# HC32F558 register map
File version: 1.0
CPU: CM4 r0p1, little endian, MPU, FPU, 4 interrupt priority bits
Registers are 32-bit, read-write, reset 0x0 unless marked. A register's access mark holds for its fields unless they carry their own. Offsets are from the block's base; [hi:lo] are bit positions; {n}, {i} and the like mark numbered series.

## MCANRAM
Base 0x4002D800
0x00 CKCR
  [1:0] ECCMOD
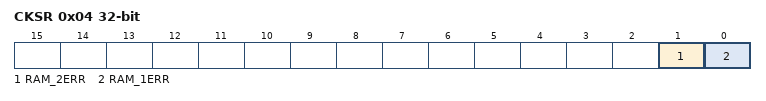
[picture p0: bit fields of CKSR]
0x04 CKSR
  [1] RAM_2ERR, [0] RAM_1ERR
0x08 EIEN
  [0] EIEN
0x0C EIBIT0
0x10 EIBIT1
  [6:0] EIBIT
0x14 ECCERRADDR ro
  [9:0] ECCERRADDR

## MPU
Base 0x40050000
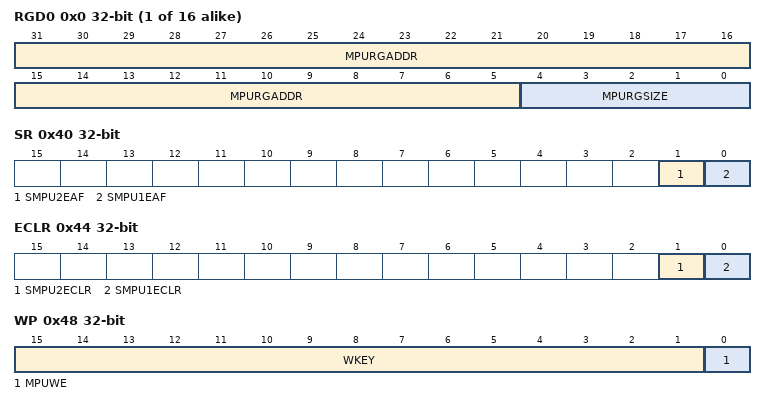
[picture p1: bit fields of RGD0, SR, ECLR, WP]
{0x0+4i} RGD{i} (i=0..15)
  [31:5] MPURGADDR, [4:0] MPURGSIZE
0x40 SR ro
  [1] SMPU2EAF, [0] SMPU1EAF
0x44 ECLR wo
  [1] SMPU2ECLR, [0] SMPU1ECLR
0x48 WP
  [15:1] WKEY wo, [0] MPUWE
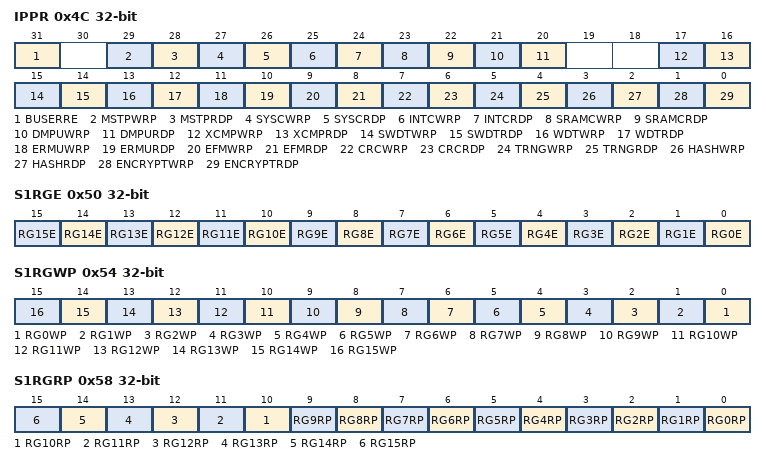
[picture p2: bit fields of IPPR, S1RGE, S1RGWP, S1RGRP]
0x4C IPPR
  [31] BUSERRE, [29] MSTPWRP, [28] MSTPRDP, [27] SYSCWRP, [26] SYSCRDP, [25] INTCWRP, [24] INTCRDP, [23] SRAMCWRP, [22] SRAMCRDP, [21] DMPUWRP, [20] DMPURDP, [17] XCMPWRP, [16] XCMPRDP, [15] SWDTWRP, [14] SWDTRDP, [13] WDTWRP, [12] WDTRDP, [11] ERMUWRP, [10] ERMURDP, [9] EFMWRP, [8] EFMRDP, [7] CRCWRP, [6] CRCRDP, [5] TRNGWRP, [4] TRNGRDP, [3] HASHWRP, [2] HASHRDP, [1] ENCRYPTWRP, [0] ENCRYPTRDP
0x50 S1RGE
  [n] RG{n}E (n=0..15)
0x54 S1RGWP
  [n] RG{n}WP (n=0..15)
0x58 S1RGRP
  [n] RG{n}RP (n=0..15)
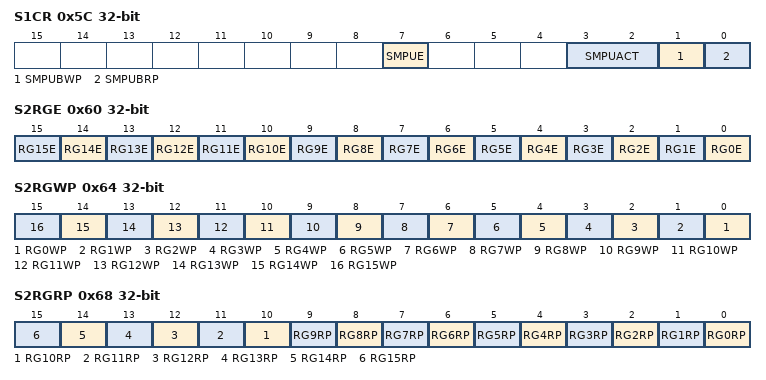
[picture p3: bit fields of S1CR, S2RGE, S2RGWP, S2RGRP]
0x5C S1CR
  [7] SMPUE, [3:2] SMPUACT, [1] SMPUBWP, [0] SMPUBRP
0x60 S2RGE
  [n] RG{n}E (n=0..15)
0x64 S2RGWP
  [n] RG{n}WP (n=0..15)
0x68 S2RGRP
  [n] RG{n}RP (n=0..15)
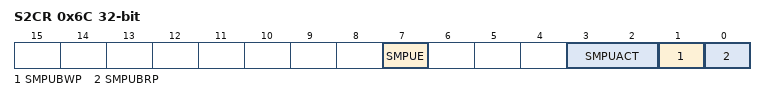
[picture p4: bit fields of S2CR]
0x6C S2CR
  [7] SMPUE, [3:2] SMPUACT, [1] SMPUBWP, [0] SMPUBRP

## OTS
Base 0x4004A800
0x00 CTL 16-bit
  [0] OTSE
0x08 PDR0 16-bit ro
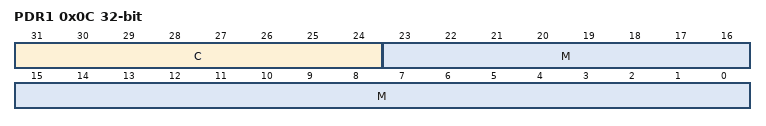
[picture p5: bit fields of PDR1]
0x0C PDR1 ro
  [31:24] C, [23:0] M

## PERIC
Base 0x40055400
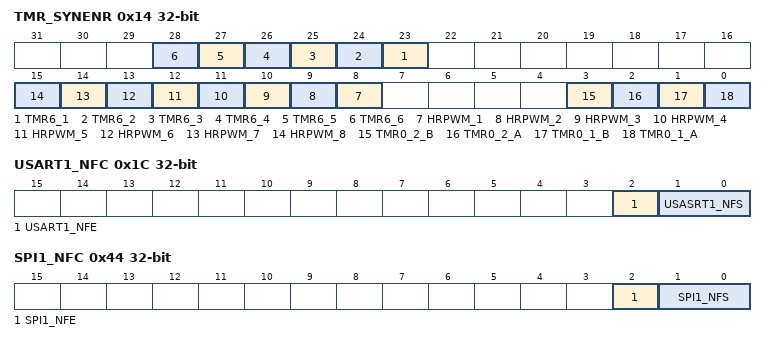
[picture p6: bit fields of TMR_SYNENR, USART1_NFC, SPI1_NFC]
0x14 TMR_SYNENR
  [n+22] TMR6_{n} (n=1..6), [n+7] HRPWM_{n} (n=1..8), [3] TMR0_2_B, [2] TMR0_2_A, [1] TMR0_1_B, [0] TMR0_1_A
0x1C USART1_NFC
  [2] USART1_NFE, [1:0] USASRT1_NFS
0x44 SPI1_NFC
  [2] SPI1_NFE, [1:0] SPI1_NFS

## PID1 — desc PID
Base 0x40057000
Same registers: PID2 0x40057100
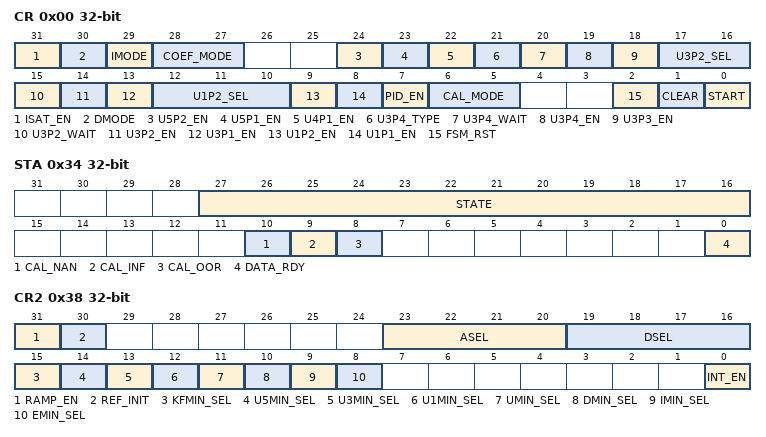
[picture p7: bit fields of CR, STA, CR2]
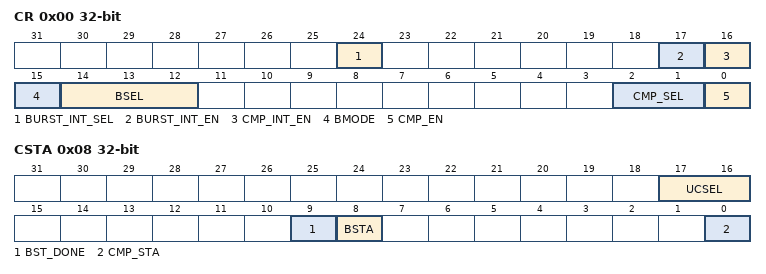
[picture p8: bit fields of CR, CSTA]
0x00 CR
  [31] ISAT_EN, [30] DMODE, [29] IMODE, [28:27] COEF_MODE, [24] U5P2_EN, [23] U5P1_EN, [22] U4P1_EN, [21] U3P4_TYPE, [20] U3P4_WAIT, [19] U3P4_EN, [18] U3P3_EN, [17:16] U3P2_SEL, [15] U3P2_WAIT, [14] U3P2_EN, [13] U3P1_EN, [12:10] U1P2_SEL, [9] U1P2_EN, [8] U1P1_EN, [7] PID_EN, [6:5] CAL_MODE, [2] FSM_RST wo, [1] CLEAR wo, [0] START wo
0x04 REF
0x08 AVAL
0x0C EMAX
0x10 EMIN
0x14 IMAX
0x18 IMIN
0x1C DMAX
0x20 DMIN
0x24 UMAX
0x28 UMIN
0x2C U1MAX
0x30 U1MIN
0x34 STA
  [27:16] STATE, [10] CAL_NAN, [9] CAL_INF, [8] CAL_OOR, [0] DATA_RDY
0x38 CR2
  [31] RAMP_EN, [30] REF_INIT, [23:20] ASEL, [19:16] DSEL, [15] KFMIN_SEL, [14] U5MIN_SEL, [13] U3MIN_SEL, [12] U1MIN_SEL, [11] UMIN_SEL, [10] DMIN_SEL, [9] IMIN_SEL, [8] EMIN_SEL, [0] INT_EN
{0x30+0xC*i} KP{i} (i=1..3)
{0x34+0xC*i} KI{i} (i=1..3)
{0x38+0xC*i} KD{i} (i=1..3)
0x60 KDF1
0x64 CSTH1
0x68 CSTH2
0x6C DLY1
0x70 DLY2
0x74 ERR ro
0x78 PVAL ro
0x7C IVAL ro
0x80 DVAL ro
0x84 U ro
{0x84+4i} U{i} ro (i=1..4)
0x98 U1P1
0x9C U3P1
0xA0 U4P1
0xA4 UF ro
0xA8 U1P2 ro
0xAC U3P2 ro
0xB0 U3P3
0xB4 U3P4 ro
0xB8 U5P1
0xBC U5P2
0xC0 U3MAX
0xC4 U3MIN
0xC8 U5MAX
0xCC U5MIN
0xD0 REF_FIN
0xD4 REF_STEP
0xD8 U5 ro
0xDC U5F ro
0xE0 KF_ACT ro
0xE4 KP_ACT ro
0xE8 KI_ACT ro
0xEC KD_ACT ro
0xF0 KDF2
0xF4 KDF3
0xF8 KDF_ACT ro

## PID_CMP
Base 0x40057400
0x00 CR
  [24] BURST_INT_SEL, [17] BURST_INT_EN, [16] CMP_INT_EN, [15] BMODE, [14:12] BSEL, [2:1] CMP_SEL, [0] CMP_EN
0x04 UC ro
0x08 CSTA
  [17:16] UCSEL ro, [9] BST_DONE, [8] BSTA, [0] CMP_STA
0x20 BTH
0x24 BMCMP ro
0x28 BMPU ro

## PLA
Base 0x4004FC00
0x00 GCTL
  [15:0] EN
0x0C STAT ro
  [15:0] OUT
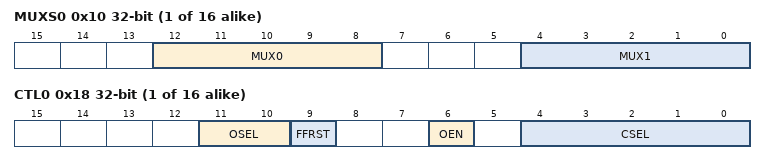
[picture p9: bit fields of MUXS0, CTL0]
{0x10+0xC*i} MUXS{i} (i=0..15)
  [12:8] MUX0, [4:0] MUX1
{0x14+0xC*i} LUTCTL{i} (i=0..15)
  [7:0] LUTCTL
{0x18+0xC*i} CTL{i} (i=0..15)
  [11:10] OSEL, [9] FFRST, [6] OEN, [4:0] CSEL

## PWC
Base 0x40048000; alternate view of CMU
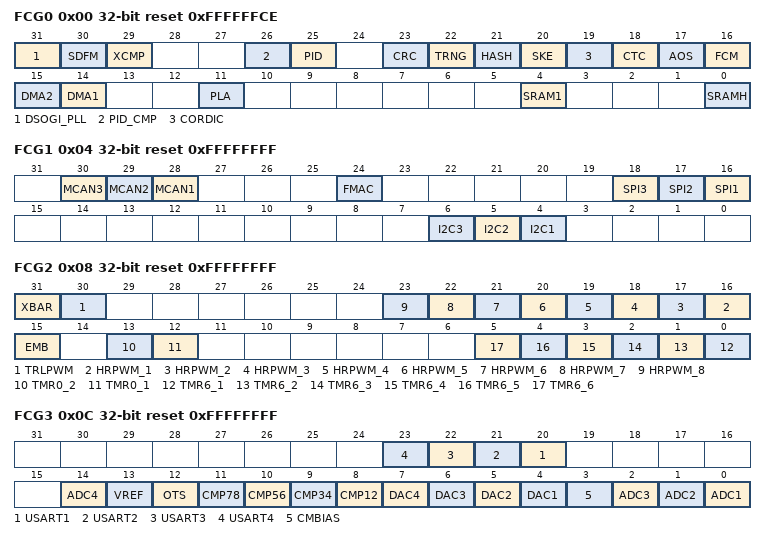
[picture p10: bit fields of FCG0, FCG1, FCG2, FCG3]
0x00 FCG0 reset 0xFFFFFFCE
  [31] DSOGI_PLL, [30] SDFM, [29] XCMP, [26] PID_CMP, [25] PID, [23] CRC, [22] TRNG, [21] HASH, [20] SKE, [19] CORDIC, [18] CTC, [17] AOS, [16] FCM, [15] DMA2, [14] DMA1, [11] PLA, [4] SRAM1, [0] SRAMH
0x04 FCG1 reset 0xFFFFFFFF
  [30] MCAN3, [29] MCAN2, [28] MCAN1, [24] FMAC, [18] SPI3, [17] SPI2, [16] SPI1, [6] I2C3, [5] I2C2, [4] I2C1
0x08 FCG2 reset 0xFFFFFFFF
  [31] XBAR, [30] TRLPWM, [n+15] HRPWM_{n} (n=1..8), [15] EMB, [13] TMR0_2, [12] TMR0_1, [n-1] TMR6_{n} (n=1..6)
0x0C FCG3 reset 0xFFFFFFFF
  [n+19] USART{n} (n=1..4), [14] ADC4, [13] VREF, [12] OTS, [11] CMP78, [10] CMP56, [9] CMP34, [8] CMP12, [n+3] DAC{n} (n=1..4), [3] CMBIAS, [2] ADC3, [1] ADC2, [0] ADC1
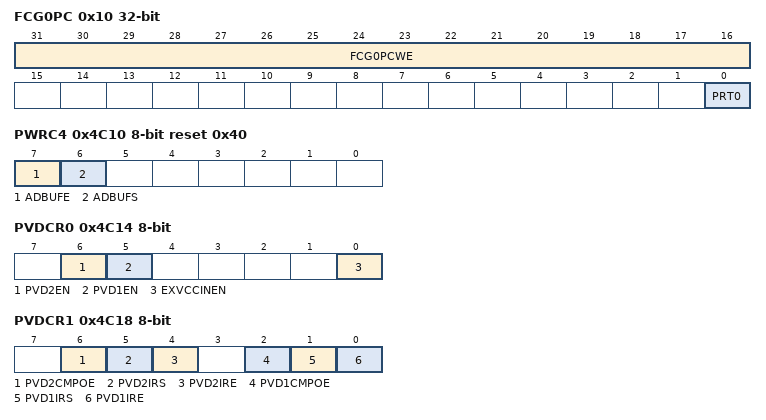
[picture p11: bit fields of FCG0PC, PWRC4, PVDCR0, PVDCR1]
0x10 FCG0PC
  [31:16] FCG0PCWE wo, [0] PRT0
0x4C04 PWRC1 8-bit reset 0xC0
  [1:0] VPLLSD
0x4C10 PWRC4 8-bit reset 0x40
  [7] ADBUFE, [6] ADBUFS
0x4C14 PVDCR0 8-bit
  [6] PVD2EN, [5] PVD1EN, [0] EXVCCINEN
0x4C18 PVDCR1 8-bit
  [6] PVD2CMPOE, [5] PVD2IRS, [4] PVD2IRE, [2] PVD1CMPOE, [1] PVD1IRS, [0] PVD1IRE
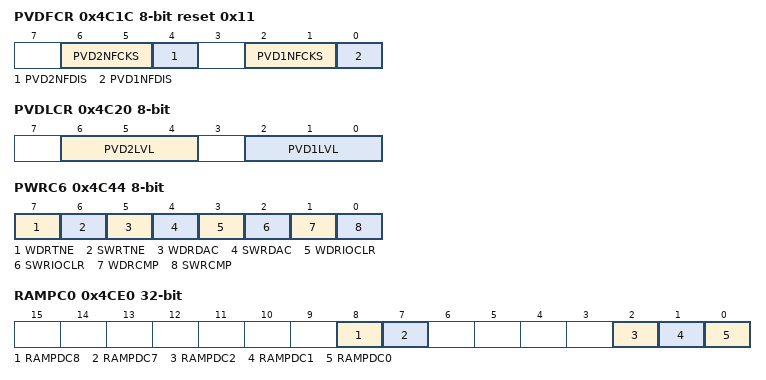
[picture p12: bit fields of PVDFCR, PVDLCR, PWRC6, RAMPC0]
0x4C1C PVDFCR 8-bit reset 0x11
  [6:5] PVD2NFCKS, [4] PVD2NFDIS, [2:1] PVD1NFCKS, [0] PVD1NFDIS
0x4C20 PVDLCR 8-bit
  [6:4] PVD2LVL, [2:0] PVD1LVL
0x4C44 PWRC6 8-bit
  [7] WDRTNE, [6] SWRTNE, [5] WDRDAC, [4] SWRDAC, [3] WDRIOCLR, [2] SWRIOCLR, [1] WDRCMP, [0] SWRCMP
0x4CE0 RAMPC0
  [8] RAMPDC8, [7] RAMPDC7, [2] RAMPDC2, [1] RAMPDC1, [0] RAMPDC0
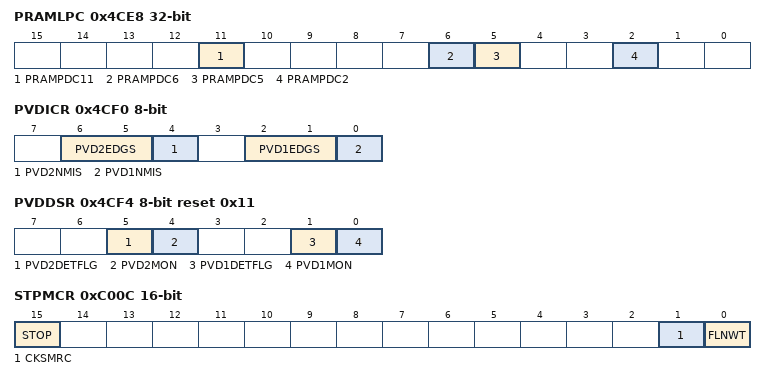
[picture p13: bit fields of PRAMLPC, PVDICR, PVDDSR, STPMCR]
0x4CE8 PRAMLPC
  [11] PRAMPDC11, [6] PRAMPDC6, [5] PRAMPDC5, [2] PRAMPDC2
0x4CEC LPMCSR 16-bit
  [0] LPMF
0x4CEE LPMCSCR 16-bit
  [0] LPMFC
0x4CF0 PVDICR 8-bit
  [6:5] PVD2EDGS, [4] PVD2NMIS, [2:1] PVD1EDGS, [0] PVD1NMIS
0x4CF4 PVDDSR 8-bit reset 0x11
  [5] PVD2DETFLG, [4] PVD2MON, [1] PVD1DETFLG, [0] PVD1MON
0xC00C STPMCR 16-bit
  [15] STOP, [1] CKSMRC, [0] FLNWT
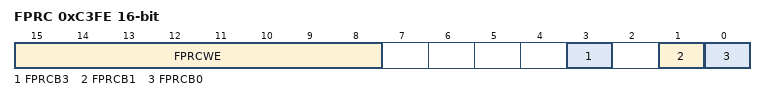
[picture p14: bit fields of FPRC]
0xC3FE FPRC 16-bit
  [15:8] FPRCWE, [3] FPRCB3, [1] FPRCB1, [0] FPRCB0
